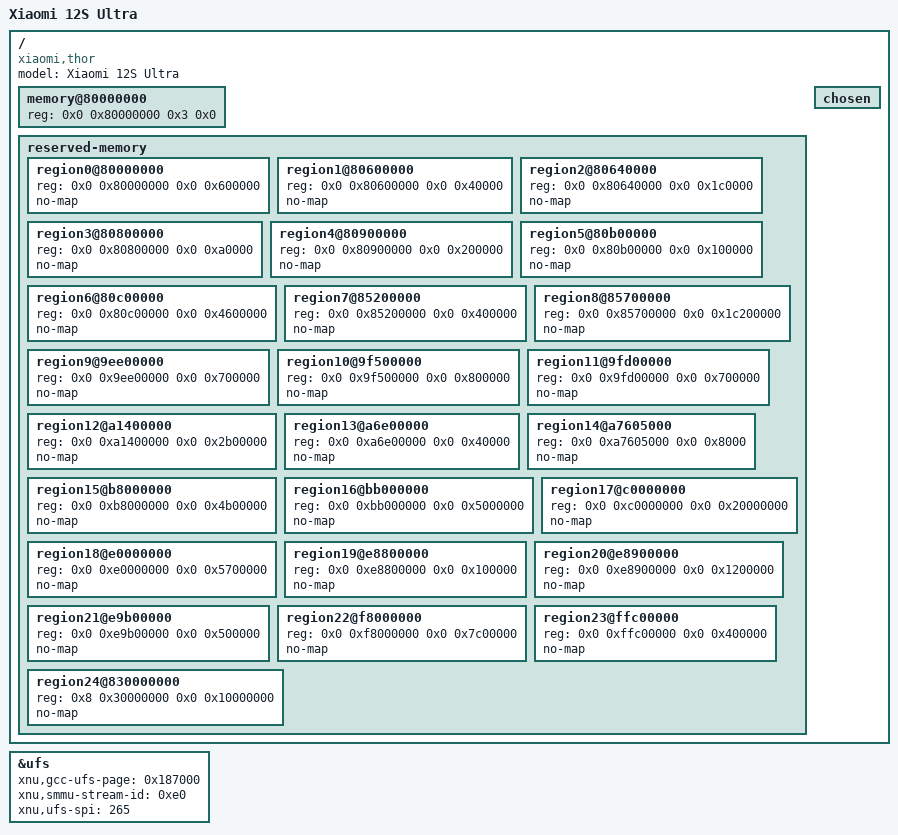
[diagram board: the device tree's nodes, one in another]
/dts-v1/;
/include/ "sm8475.dtsi"
/ {
    model = "Xiaomi 12S Ultra";
    compatible = "xiaomi,thor", "qcom,sm8475";
    /* 12 GiB from 0x80000000, same SoC as pong. Format 2 reads /memory as a
       single reg pair; firmware-owned ranges below stay in reserved-memory. */
    memory@80000000 { device_type = "memory"; reg = <0x0 0x80000000 0x3 0x0>; };
    reserved-memory {
        #address-cells = <2>;
        #size-cells = <2>;
        ranges;
        /* Same SM8475 firmware layout as pong (measured on both devices) */
        region0@80000000 { reg = <0x0 0x80000000 0x0 0x600000>; no-map; };
        region1@80600000 { reg = <0x0 0x80600000 0x0 0x40000>; no-map; };
        region2@80640000 { reg = <0x0 0x80640000 0x0 0x1c0000>; no-map; };
        region3@80800000 { reg = <0x0 0x80800000 0x0 0xa0000>; no-map; };
        region4@80900000 { reg = <0x0 0x80900000 0x0 0x200000>; no-map; };
        region5@80b00000 { reg = <0x0 0x80b00000 0x0 0x100000>; no-map; };
        region6@80c00000 { reg = <0x0 0x80c00000 0x0 0x4600000>; no-map; };
        region7@85200000 { reg = <0x0 0x85200000 0x0 0x400000>; no-map; };
        region8@85700000 { reg = <0x0 0x85700000 0x0 0x1c200000>; no-map; };
        region9@9ee00000 { reg = <0x0 0x9ee00000 0x0 0x700000>; no-map; };
        region10@9f500000 { reg = <0x0 0x9f500000 0x0 0x800000>; no-map; };
        region11@9fd00000 { reg = <0x0 0x9fd00000 0x0 0x700000>; no-map; };
        region12@a1400000 { reg = <0x0 0xa1400000 0x0 0x2b00000>; no-map; };
        region13@a6e00000 { reg = <0x0 0xa6e00000 0x0 0x40000>; no-map; };
        region14@a7605000 { reg = <0x0 0xa7605000 0x0 0x8000>; no-map; };
        region15@b8000000 { reg = <0x0 0xb8000000 0x0 0x4b00000>; no-map; };
        region16@bb000000 { reg = <0x0 0xbb000000 0x0 0x5000000>; no-map; };
        region17@c0000000 { reg = <0x0 0xc0000000 0x0 0x20000000>; no-map; };
        region18@e0000000 { reg = <0x0 0xe0000000 0x0 0x5700000>; no-map; };
        region19@e8800000 { reg = <0x0 0xe8800000 0x0 0x100000>; no-map; };
        region20@e8900000 { reg = <0x0 0xe8900000 0x0 0x1200000>; no-map; };
        region21@e9b00000 { reg = <0x0 0xe9b00000 0x0 0x500000>; no-map; };
        region22@f8000000 { reg = <0x0 0xf8000000 0x0 0x7c00000>; no-map; };
        region23@ffc00000 { reg = <0x0 0xffc00000 0x0 0x400000>; no-map; };
        region24@830000000 { reg = <0x8 0x30000000 0x0 0x10000000>; no-map; };
    };

    chosen {
        #address-cells = <2>;
        #size-cells = <2>;
        ranges;
    };
};
/* UFS: same SM8475 controller, stream 0xE0, enabled for the thor driver */
&ufs {
    status = "okay";
    /* Same SoC: GCC UFS page, SMMU stream ID, and SPI bus number as pong */
    xnu,gcc-ufs-page = /bits/ 64 <0x187000>;
    xnu,smmu-stream-id = <0xe0>;
    xnu,ufs-spi = <265>;
};
